AUTOSAR XML (schema 4-0-3)
standard types defined: Boolean, UInt16, UInt32, UInt8
package /AUTOSAR_Platform/DataConstrs
  range DC_Boolean: raw 0..1
  range DC_UInt16: raw 0..65535
  range DC_UInt8: raw 0..255
package /PATAC/MSM/ComponentTypes
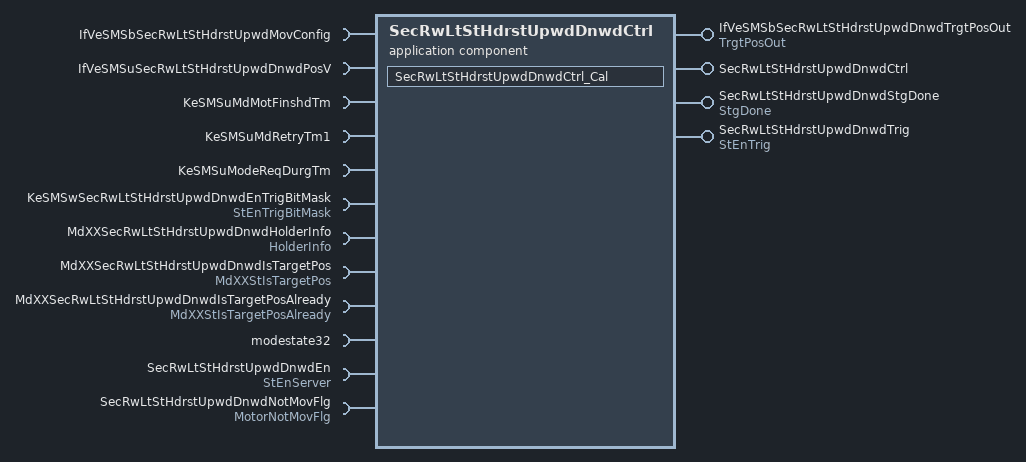
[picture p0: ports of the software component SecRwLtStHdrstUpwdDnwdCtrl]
  application sw component type SecRwLtStHdrstUpwdDnwdCtrl
    4 x provide port:
      IfVeSMSbSecRwLtStHdrstUpwdDnwdTrgtPosOut: nonqueued-sender-com-spec{data-element=TrgtPosOut/Val, init-value=0}, provided-interface=TrgtPosOut
      SecRwLtStHdrstUpwdDnwdCtrl: server-com-spec{operation=Cal, queue-length=1}, provided-interface=SecRwLtStHdrstUpwdDnwdCtrl
      SecRwLtStHdrstUpwdDnwdStgDone: nonqueued-sender-com-spec{data-element=StgDone/Val, init-value=0}, provided-interface=StgDone
      SecRwLtStHdrstUpwdDnwdTrig: nonqueued-sender-com-spec{data-element=StEnTrig/Val, init-value=0}, provided-interface=StEnTrig
    12 x require port:
      IfVeSMSbSecRwLtStHdrstUpwdMovConfig: nonqueued-receiver-com-spec{data-element=IfVeSMSbSecRwLtStHdrstUpwdMovConfig/Val, filter=data-filter-type=ALWAYS, init-value=0}, required-interface=IfVeSMSbSecRwLtStHdrstUpwdMovConfig
      IfVeSMSuSecRwLtStHdrstUpwdDnwdPosV: nonqueued-receiver-com-spec{data-element=IfVeSMSuSecRwLtStHdrstUpwdDnwdPosV/Val, filter=data-filter-type=ALWAYS, init-value=0}, required-interface=IfVeSMSuSecRwLtStHdrstUpwdDnwdPosV
      KeSMSuMdMotFinshdTm: parameter-require-com-spec{init-value=0, parameter=KeSMSuMdMotFinshdTm/Val}, required-interface=KeSMSuMdMotFinshdTm
      KeSMSuMdRetryTm1: parameter-require-com-spec{init-value=0, parameter=KeSMSuMdRetryTm1/Val}, required-interface=KeSMSuMdRetryTm1
      KeSMSuModeReqDurgTm: parameter-require-com-spec{init-value=0, parameter=KeSMSuModeReqDurgTm/Val}, required-interface=KeSMSuModeReqDurgTm
      KeSMSwSecRwLtStHdrstUpwdDnwdEnTrigBitMask: parameter-require-com-spec{init-value=6153, parameter=StEnTrigBitMask/Val}, required-interface=StEnTrigBitMask
      MdXXSecRwLtStHdrstUpwdDnwdHolderInfo: nonqueued-receiver-com-spec{data-element=HolderInfo/Val, filter=data-filter-type=ALWAYS, init-value=0}, required-interface=HolderInfo
      MdXXSecRwLtStHdrstUpwdDnwdIsTargetPos: nonqueued-receiver-com-spec{data-element=MdXXStIsTargetPos/Val, filter=data-filter-type=ALWAYS, init-value=0}, required-interface=MdXXStIsTargetPos
      MdXXSecRwLtStHdrstUpwdDnwdIsTargetPosAlready: nonqueued-receiver-com-spec{data-element=MdXXStIsTargetPosAlready/Val, filter=data-filter-type=ALWAYS, init-value=0}, required-interface=MdXXStIsTargetPosAlready
      modestate32: nonqueued-receiver-com-spec{data-element=modestate32/Val, filter=data-filter-type=ALWAYS, init-value=0}, required-interface=modestate32
      SecRwLtStHdrstUpwdDnwdEn: required-com-specs=[Clear, Get, Set], required-interface=StEnServer
      SecRwLtStHdrstUpwdDnwdNotMovFlg: nonqueued-receiver-com-spec{data-element=MotorNotMovFlg/Val, filter=data-filter-type=ALWAYS, init-value=0}, required-interface=MotorNotMovFlg
    behavior SecRwLtStHdrstUpwdDnwdCtrl_InternalBehavior
      operation invoked event OIT_SecRwLtStHdrstUpwdDnwdCtrl_Cal_SecRwLtStHdrstUpwdDnwdCtrl_Cal: start-on-event=SecRwLtStHdrstUpwdDnwdCtrl_Cal, operation=SecRwLtStHdrstUpwdDnwdCtrl.Cal
      runnable SecRwLtStHdrstUpwdDnwdCtrl_Cal
        data-receive-point-by-arguments:
          7 x access:
            REC_IfVeSMSbSecRwLtStHdrstUpwdMovConfig_Val: accessed-variable=IfVeSMSbSecRwLtStHdrstUpwdMovConfig.Val
            REC_IfVeSMSuSecRwLtStHdrstUpwdDnwdPosV_Val: accessed-variable=IfVeSMSuSecRwLtStHdrstUpwdDnwdPosV.Val
            REC_MdXXSecRwLtStHdrstUpwdDnwdHolderInfo_Val: accessed-variable=MdXXSecRwLtStHdrstUpwdDnwdHolderInfo.Val
            REC_MdXXSecRwLtStHdrstUpwdDnwdIsTargetPos_Val: accessed-variable=MdXXSecRwLtStHdrstUpwdDnwdIsTargetPos.Val
            REC_MdXXSecRwLtStHdrstUpwdDnwdIsTargetPosAlready_Val: accessed-variable=MdXXSecRwLtStHdrstUpwdDnwdIsTargetPosAlready.Val
            REC_modestate32_Val: accessed-variable=modestate32.Val
            REC_SecRwLtStHdrstUpwdDnwdNotMovFlg_Val: accessed-variable=SecRwLtStHdrstUpwdDnwdNotMovFlg.Val
        data-send-points:
          access SEND_IfVeSMSbSecRwLtStHdrstUpwdDnwdTrgtPosOut_Val: accessed-variable=IfVeSMSbSecRwLtStHdrstUpwdDnwdTrgtPosOut.Val
          access SEND_SecRwLtStHdrstUpwdDnwdStgDone_Val: accessed-variable=SecRwLtStHdrstUpwdDnwdStgDone.Val
          access SEND_SecRwLtStHdrstUpwdDnwdTrig_Val: accessed-variable=SecRwLtStHdrstUpwdDnwdTrig.Val
        4 x parameter access:
          PA_KeSMSuMdMotFinshdTm_Val: accessed-parameter=KeSMSuMdMotFinshdTm.Val
          PA_KeSMSuMdRetryTm1_Val: accessed-parameter=KeSMSuMdRetryTm1.Val
          PA_KeSMSuModeReqDurgTm_Val: accessed-parameter=KeSMSuModeReqDurgTm.Val
          PA_KeSMSwSecRwLtStHdrstUpwdDnwdEnTrigBitMask_Val: accessed-parameter=KeSMSwSecRwLtStHdrstUpwdDnwdEnTrigBitMask.Val
        sync call SC_SecRwLtStHdrstUpwdDnwdEn_Get: operation=SecRwLtStHdrstUpwdDnwdEn.Get, timeout=0
  swc implementation SecRwLtStHdrstUpwdDnwdCtrl_Implementation: behavior=SecRwLtStHdrstUpwdDnwdCtrl_InternalBehavior
    code-descriptors:
      code Default: artifact-descriptors=autosar-engineering-object={short-label=Default, category=SWSRC}
package /PATAC/MSM/ModeAdjust/CalPortInterface
  parameter interface KeSMSuMdMotFinshdTm
    parameter data prototype Val: sw-calibration-access=READ-WRITE, type=UInt16
  parameter interface KeSMSuModeReqDurgTm
    parameter data prototype Val: sw-calibration-access=READ-WRITE, type=UInt16
  parameter interface StEnTrigBitMask
    parameter data prototype Val: sw-calibration-access=READ-WRITE, type=UInt32
package /PATAC/MSM/ModeAdjust/Interfaces
  sender receiver interface IfVeSMSuSecRwLtStHdrstUpwdDnwdPosV: invalidation-policy{data-element=IfVeSMSuSecRwLtStHdrstUpwdDnwdPosV/Val, handle-invalid=DONT-INVALIDATE}
    data Val: type=Boolean
package /PATAC/MSM/ModeAdjust/PortInterface
  client server interface SecRwLtStHdrstUpwdDnwdCtrl
    operation Cal
  client server interface StEnServer
    operation Clear
      arg data: type=UInt8, direction=IN, server-argument-impl-policy=USE-ARGUMENT-TYPE
    operation Get
      arg data: type=UInt32, direction=OUT, server-argument-impl-policy=USE-ARGUMENT-TYPE
    operation Set
      arg data: type=UInt8, direction=IN, server-argument-impl-policy=USE-ARGUMENT-TYPE
  8 x sender receiver interface:
    HolderInfo: invalidation-policy{data-element=HolderInfo/Val, handle-invalid=DONT-INVALIDATE}
      data Val: type=UInt32
    MdXXStIsTargetPos: invalidation-policy{data-element=MdXXStIsTargetPos/Val, handle-invalid=DONT-INVALIDATE}
      data Val: type=UInt32
    MdXXStIsTargetPosAlready: invalidation-policy{data-element=MdXXStIsTargetPosAlready/Val, handle-invalid=DONT-INVALIDATE}
      data Val: type=UInt32
    modestate32: invalidation-policy{data-element=modestate32/Val, handle-invalid=DONT-INVALIDATE}
      data Val: type=UInt32
    MotorNotMovFlg: invalidation-policy{data-element=MotorNotMovFlg/Val, handle-invalid=DONT-INVALIDATE}
      data Val: type=Boolean
    StEnTrig: invalidation-policy{data-element=StEnTrig/Val, handle-invalid=DONT-INVALIDATE}
      data Val: type=Boolean
    StgDone: invalidation-policy{data-element=StgDone/Val, handle-invalid=DONT-INVALIDATE}
      data Val: type=Boolean
    TrgtPosOut: invalidation-policy{data-element=TrgtPosOut/Val, handle-invalid=DONT-INVALIDATE}
      data Val: type=Boolean
package /PATAC/MSM/PortInterfaces
  parameter interface KeSMSuMdRetryTm1
    parameter data prototype Val: sw-calibration-access=READ-WRITE, type=UInt8
  sender receiver interface IfVeSMSbSecRwLtStHdrstUpwdMovConfig: invalidation-policy{data-element=IfVeSMSbSecRwLtStHdrstUpwdMovConfig/Val, handle-invalid=DONT-INVALIDATE}
    data Val: type=Boolean
